# CPU_ICB register map
Vendor: Texas Instruments
Peripheral module from a debugger description file (folder CC26x4).
Registers are 32-bit, read-only, reset 0x0 unless marked. A register's access mark holds for its fields unless they carry their own. Offsets are as the file gives them; lines under a group give offsets from that group; [hi:lo] are bit positions; {n}, {i} and the like mark numbered series; 'fields as' and 'values as' point back to an identical list; <NAME> marks a mode.

## CPU_ICB — Cortex-M's Implementation Control Block (ICB)
0x04 ICTR — Provides information about the interrupt controller
  [3:0] INTLINESNUM — Indicates the number of the highest implemented register in each of the NVIC control register sets, or in the case of NVIC_IPR*n, 4xINTLINESNUM
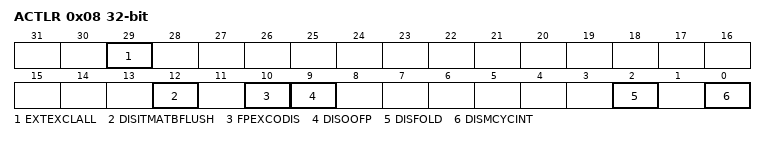
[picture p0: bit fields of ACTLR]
0x08 ACTLR access per field — Provides IMPLEMENTATION DEFINED configuration and control options
  [29] EXTEXCLALL rw — External Exclusives Allowed with no MPU
  [12] DISITMATBFLUSH rw — Disable ATB Flush
  [10] FPEXCODIS rw — Disable FPU exception outputs
  [9] DISOOFP rw — Disable out-of-order FP instruction completion
  [2] DISFOLD rw — Disable dual-issue.
  [0] DISMCYCINT rw — Disable dual-issue.
